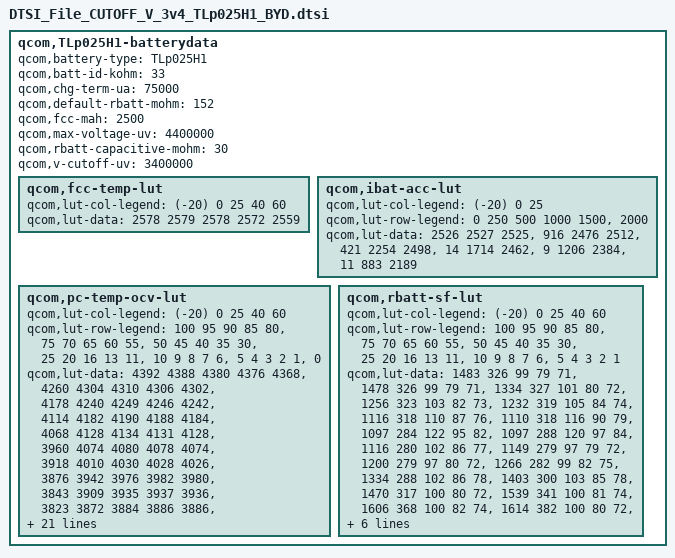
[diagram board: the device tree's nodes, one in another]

qcom,TLp025H1-batterydata {
	qcom,battery-type = "TLp025H1";
	qcom,batt-id-kohm = <33>;
	qcom,chg-term-ua = <75000>;
	qcom,default-rbatt-mohm = <152>;
	qcom,fcc-mah = <2500>;
	qcom,max-voltage-uv = <4400000>;
	qcom,rbatt-capacitive-mohm = <30>;
	qcom,v-cutoff-uv = <3400000>;

	qcom,fcc-temp-lut {
		qcom,lut-col-legend = <(-20) 0 25 40 60>;
		qcom,lut-data = <2578 2579 2578 2572 2559>;
	};

	qcom,ibat-acc-lut {
		qcom,lut-col-legend = <(-20) 0 25>;
		qcom,lut-row-legend = <0 250 500 1000 1500>,
					<2000>;
		qcom,lut-data = <2526 2527 2525>,
				<916 2476 2512>,
				<421 2254 2498>,
				<14 1714 2462>,
				<9 1206 2384>,
				<11 883 2189>;
	};

	qcom,pc-temp-ocv-lut {
		qcom,lut-col-legend = <(-20) 0 25 40 60>;
		qcom,lut-row-legend = <100 95 90 85 80>,
					<75 70 65 60 55>,
					<50 45 40 35 30>,
					<25 20 16 13 11>,
					<10 9 8 7 6>,
					<5 4 3 2 1>,
					<0>;
		qcom,lut-data = <4392 4388 4380 4376 4368>,
				<4260 4304 4310 4306 4302>,
				<4178 4240 4249 4246 4242>,
				<4114 4182 4190 4188 4184>,
				<4068 4128 4134 4131 4128>,
				<3960 4074 4080 4078 4074>,
				<3918 4010 4030 4028 4026>,
				<3876 3942 3976 3982 3980>,
				<3843 3909 3935 3937 3936>,
				<3823 3872 3884 3886 3886>,
				<3808 3841 3849 3849 3849>,
				<3794 3814 3824 3824 3823>,
				<3782 3793 3803 3804 3802>,
				<3768 3779 3786 3787 3786>,
				<3753 3768 3772 3770 3765>,
				<3736 3754 3757 3750 3738>,
				<3716 3736 3740 3730 3716>,
				<3697 3720 3718 3710 3696>,
				<3679 3708 3698 3690 3676>,
				<3663 3700 3690 3682 3671>,
				<3653 3696 3689 3681 3670>,
				<3641 3692 3687 3680 3668>,
				<3626 3688 3686 3678 3667>,
				<3610 3682 3682 3676 3663>,
				<3586 3668 3675 3667 3652>,
				<3557 3642 3648 3640 3622>,
				<3518 3601 3603 3594 3575>,
				<3462 3538 3542 3534 3514>,
				<3372 3455 3462 3452 3430>,
				<3230 3328 3330 3329 3300>,
				<3015 3000 3022 3000 3000>;
	};

	qcom,rbatt-sf-lut {
		qcom,lut-col-legend = <(-20) 0 25 40 60>;
		qcom,lut-row-legend = <100 95 90 85 80>,
					<75 70 65 60 55>,
					<50 45 40 35 30>,
					<25 20 16 13 11>,
					<10 9 8 7 6>,
					<5 4 3 2 1>;
		qcom,lut-data = <1483 326 99 79 71>,
				<1478 326 99 79 71>,
				<1334 327 101 80 72>,
				<1256 323 103 82 73>,
				<1232 319 105 84 74>,
				<1116 318 110 87 76>,
				<1110 318 116 90 79>,
				<1097 284 122 95 82>,
				<1097 288 120 97 84>,
				<1116 280 102 86 77>,
				<1149 279 97 79 72>,
				<1200 279 97 80 72>,
				<1266 282 99 82 75>,
				<1334 288 102 86 78>,
				<1403 300 103 85 78>,
				<1470 317 100 80 72>,
				<1539 341 100 81 74>,
				<1606 368 100 82 74>,
				<1614 382 100 80 72>,
				<1668 401 100 78 72>,
				<1697 417 101 80 74>,
				<1769 433 103 82 76>,
				<1888 455 107 85 79>,
				<2062 481 111 88 82>,
				<2276 501 115 89 82>,
				<2588 525 110 86 75>,
				<3043 559 111 86 76>,
				<3759 624 116 87 79>,
				<5647 723 127 95 87>,
				<11295 1446 220 121 117>;
	};
};
/* TEST_DB_ID=TEST_ID_NOT_SET */
